VERSION ""

NS_ :

BS_:

BU_: XXX X

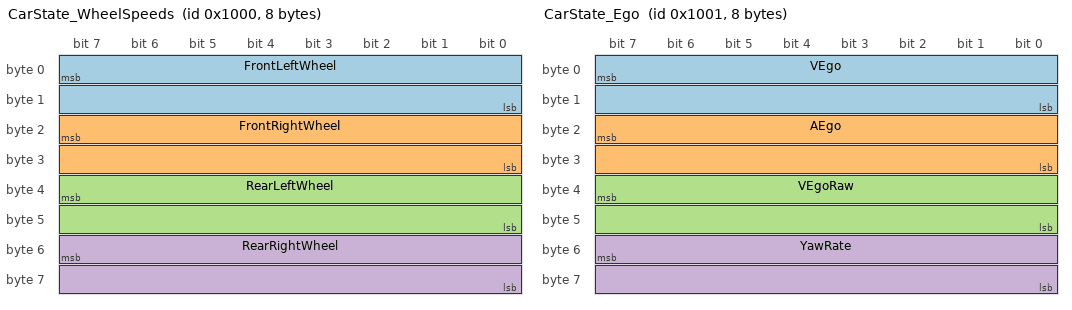
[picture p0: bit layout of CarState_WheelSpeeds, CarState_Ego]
BO_ 4096 CarState_WheelSpeeds: 8 XXX
 SG_ FrontLeftWheel : 7|16@0- (0.001,0) [0|1000] "" XXX
 SG_ FrontRightWheel : 23|16@0- (0.001,0) [0|1000] "" XXX
 SG_ RearLeftWheel : 39|16@0- (0.001,0) [0|1000] "" XXX
 SG_ RearRightWheel : 55|16@0- (0.001,0) [0|1000] "" XXX

BO_ 4097 CarState_Ego: 8 XXX
 SG_ VEgo : 7|16@0- (0.001,0) [0|1000] "" XXX
 SG_ AEgo : 23|16@0- (0.001,0) [0|1000] "" XXX
 SG_ VEgoRaw : 39|16@0- (0.001,0) [0|1000] "" XXX
 SG_ YawRate : 55|16@0- (0.001,0) [0|1000] "" XXX
